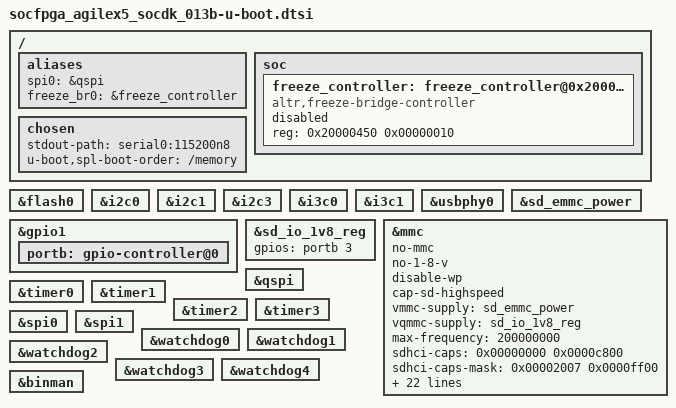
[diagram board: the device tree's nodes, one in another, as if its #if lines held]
// SPDX-License-Identifier: GPL-2.0+
/*
 * U-Boot additions for Agilex5 SocDK 013B
 *
 * Copyright (C) 2025 Altera Corporation <www.altera.com>
 */

#include "socfpga_agilex5-u-boot.dtsi"

/{
	aliases {
		spi0 = &qspi;
		freeze_br0 = &freeze_controller;
	};

	soc {
		freeze_controller: freeze_controller@0x20000450 {
			compatible = "altr,freeze-bridge-controller";
			reg = <0x20000450 0x00000010>;
			status = "disabled";
		};
	};

	/*
	 * Both Memory base address and size default info is retrieved from HW setting.
	 * Reconfiguration / Overwrite these info can be done with examples below.
	 *
	 * When LPDDR ECC is enabled, the last 1/8 of the memory region must
	 * be reserved for the Inline ECC buffer.
	 *
	 * Example for memory size with 2GB:
	 * memory {
	 *	reg = <0x0 0x80000000 0x0 0x80000000>;
	 * };
	 *
	 * Example for memory size with 8GB:
	 * memory {
	 *	reg = <0x0 0x80000000 0x0 0x80000000>,
	 *	      <0x8 0x80000000 0x1 0x80000000>;
	 * };
	 *
	 * Example for memory size with 32GB:
	 * memory {
	 *	reg = <0x0 0x80000000 0x0 0x80000000>,
	 *	      <0x8 0x80000000 0x7 0x80000000>;
	 * };
	 *
	 * Example for memory size with 512GB:
	 * memory {
	 *	reg = <0x0 0x80000000 0x0 0x80000000>,
	 *	      <0x8 0x80000000 0x7 0x80000000>,
	 *	      <0x88 0x00000000 0x78 0x00000000>;
	 * };
	 *
	 * Example for memory size with 2GB with LPDDR Inline ECC ON:
	 * memory {
	 *	reg = <0x0 0x80000000 0x0 0x70000000>;
	 * };
	 *
	 * Example for memory size with 8GB with LPDDR Inline ECC ON:
	 * memory {
	 *	reg = <0x0 0x80000000 0x0 0x80000000>,
	 *	      <0x8 0x80000000 0x1 0x40000000>;
	 * };
	 */

	chosen {
		stdout-path = "serial0:115200n8";
		u-boot,spl-boot-order = &mmc,&flash0,"/memory";
	};
};

&flash0 {
	bootph-all;
	/delete-property/ cdns,read-delay;
};

&i2c0 {
	status = "okay";
	bootph-all;
};

&i2c1 {
	status = "okay";
	bootph-all;
};

&i2c3 {
	status = "okay";
	bootph-all;
};

&i3c0 {
	bootph-all;
};

&i3c1 {
	bootph-all;
};

&usbphy0 {
	status = "okay";
};

&gpio1 {
	portb: gpio-controller@0 {
		bootph-all;
	};
};

&sd_emmc_power {
	bootph-all;
};

&sd_io_1v8_reg {
	gpios = <&portb 3 GPIO_ACTIVE_HIGH>;
	bootph-all;
};

&mmc {
	status = "okay";

	no-mmc;
	no-1-8-v;
	disable-wp;
	cap-sd-highspeed;
	vmmc-supply = <&sd_emmc_power>;
	vqmmc-supply = <&sd_io_1v8_reg>;
	max-frequency = <200000000>;
	sdhci-caps = <0x00000000 0x0000c800>;
	sdhci-caps-mask = <0x00002007 0x0000ff00>;

	/* SD card default speed (DS) and UHS-I SDR12 mode timing configuration */
	cdns,phy-dqs-timing-delay-sd-ds = <0x00780000>;
	cdns,phy-gate-lpbk-ctrl-delay-sd-ds = <0x81a40040>;
	cdns,phy-dll-slave-ctrl-sd-ds = <0x00a000fe>;
	cdns,phy-dq-timing-delay-sd-ds = <0x28000001>;

	/* SD card high speed and UHS-I SDR25 mode timing configuration */
	cdns,phy-dqs-timing-delay-sd-hs = <0x780001>;
	cdns,phy-gate-lpbk-ctrl-delay-sd-hs = <0x81a40040>;
	cdns,phy-dq-timing-delay-sd-hs = <0x10000001>;
	cdns,ctrl-hrs16-slave-ctrl-sd-hs = <0x101>;
	cdns,ctrl-hrs07-timing-delay-sd-hs = <0xA0001>;

	/* SD card UHS-I SDR50 mode timing configuration */
	cdns,phy-dqs-timing-delay-emmc-sdr = <0x780004>;
	cdns,phy-gate-lpbk-ctrl-delay-emmc-sdr = <0x80a40040>;
	cdns,phy-dll-slave-ctrl-emmc-sdr = <0x4000004>;
	cdns,phy-dq-timing-delay-emmc-sdr = <0x38000001>;
	cdns,ctrl-hrs09-timing-delay-emmc-sdr = <0xf1c1800c>;
	cdns,ctrl-hrs10-lpbk-ctrl-delay-emmc-sdr = <0x20000>;
	cdns,ctrl-hrs16-slave-ctrl-emmc-sdr = <0x101>;
	cdns,ctrl-hrs07-timing-delay-emmc-sdr = <0x90005>;

	bootph-all;
};

&qspi {
	status = "okay";
};

&timer0 {
	status = "okay";
	bootph-all;
};

&timer1 {
	status = "okay";
	bootph-all;
};

&timer2 {
	status = "okay";
	bootph-all;
};

&timer3 {
	status = "okay";
	bootph-all;
};

&spi0 {
	status = "okay";
};

&spi1 {
	status = "okay";
};

&watchdog0 {
	status = "okay";
	bootph-all;
};

&watchdog1 {
	status = "okay";
};

&watchdog2 {
	status = "okay";
};

&watchdog3 {
	status = "okay";
};

&watchdog4 {
	status = "okay";
};

#if defined(CONFIG_FIT) && !defined(CONFIG_SOCFPGA_SECURE_VAB_AUTH)
&binman {
	/delete-node/ kernel;
};
#endif
